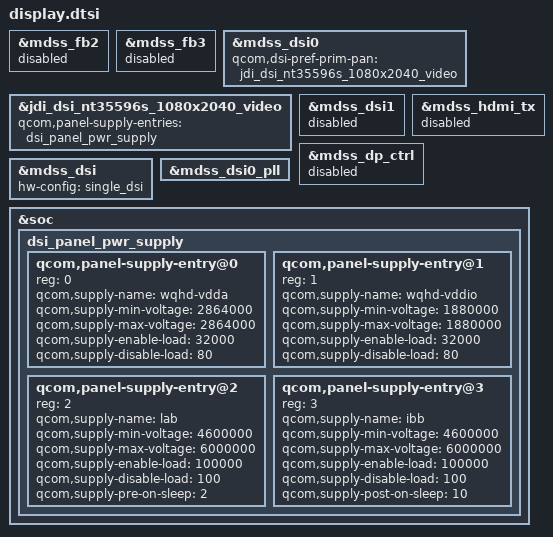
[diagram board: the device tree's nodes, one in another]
#include "nubia-dsi-panel-jdi-nt35596s-1080x2040-video.dtsi"

&mdss_fb2 {
	status = "disabled";
};
&mdss_fb3 {
	status = "disabled";
};

&mdss_dsi0 {
	qcom,dsi-pref-prim-pan = <&jdi_dsi_nt35596s_1080x2040_video>;
	/delete-property/ qcom,panel-mode-gpio;
	/delete-property/ wqhd-vdda-supply;
};

&jdi_dsi_nt35596s_1080x2040_video {
	qcom,panel-supply-entries = <&dsi_panel_pwr_supply>;
};

&mdss_dsi1 {
	status = "disabled";
	/delete-property/ wqhd-vdda-supply;
};

&mdss_hdmi_tx {
	status = "disabled";
};

&mdss_dp_ctrl {
	status = "disabled";
};

&mdss_dsi {
	hw-config = "single_dsi";
};

&mdss_dsi0_pll {
	/delete-property/ qcom,dsi-pll-ssc-en;
	/delete-property/ qcom,dsi-pll-ssc-mode;
};

&soc {
	dsi_panel_pwr_supply: dsi_panel_pwr_supply {
		#address-cells = <1>;
		#size-cells = <0>;
		
		qcom,panel-supply-entry@0 {
			reg = <0>;
			qcom,supply-name = "wqhd-vdda";
			qcom,supply-min-voltage = <2864000>;
			qcom,supply-max-voltage = <2864000>;
			qcom,supply-enable-load = <32000>;
			qcom,supply-disable-load = <80>;
		};
		
		qcom,panel-supply-entry@1 {
			reg = <1>;
			qcom,supply-name = "wqhd-vddio";
			qcom,supply-min-voltage = <1880000>;
			qcom,supply-max-voltage = <1880000>;
			qcom,supply-enable-load = <32000>;
			qcom,supply-disable-load = <80>;
		};
		
		qcom,panel-supply-entry@2 {
			reg = <2>;
			qcom,supply-name = "lab";
			qcom,supply-min-voltage = <4600000>;
			qcom,supply-max-voltage = <6000000>;
			qcom,supply-enable-load = <100000>;
			qcom,supply-disable-load = <100>;
			qcom,supply-pre-on-sleep = <2>;
		};
		
		qcom,panel-supply-entry@3 {
			reg = <3>;
			qcom,supply-name = "ibb";
			qcom,supply-min-voltage = <4600000>;
			qcom,supply-max-voltage = <6000000>;
			qcom,supply-enable-load = <100000>;
			qcom,supply-disable-load = <100>;
			qcom,supply-post-on-sleep = <10>;
		};
	};
};
